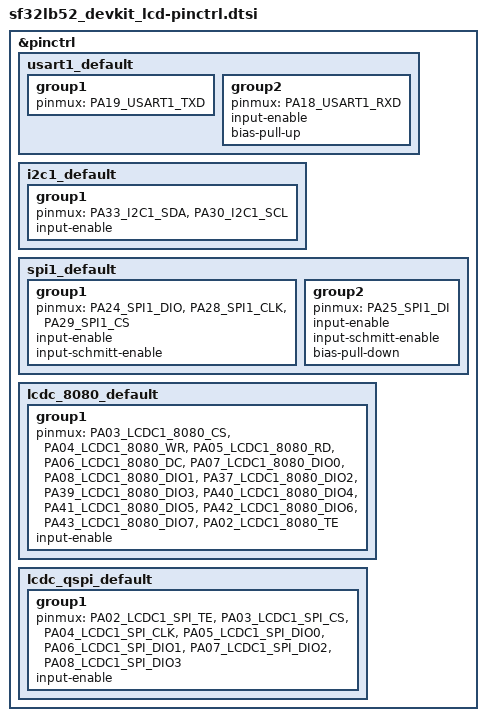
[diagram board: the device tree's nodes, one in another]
/*
 * Copyright (c) 2025 Core Devices LLC
 * SPDX-License-Identifier: Apache-2.0
 */

#include <zephyr/dt-bindings/pinctrl/sf32lb52x-pinctrl.h>

&pinctrl {
	usart1_default: usart1_default {
		group1 {
			pinmux = <PA19_USART1_TXD>;
		};

		group2 {
			pinmux = <PA18_USART1_RXD>;
			input-enable;
			bias-pull-up;
		};
	};

	i2c1_default: i2c1_default {
		group1 {
			pinmux = <PA33_I2C1_SDA>, <PA30_I2C1_SCL>;
			input-enable;
		};
	};

	spi1_default: spi1_default {
		group1 {
			pinmux = <PA24_SPI1_DIO>, <PA28_SPI1_CLK>, <PA29_SPI1_CS>;
			input-enable;
			input-schmitt-enable;
		};

		group2 {
			pinmux = <PA25_SPI1_DI>;
			input-enable;
			input-schmitt-enable;
			bias-pull-down;
		};
	};

	lcdc_8080_default: lcdc_8080_default {
		group1 {
			pinmux = <PA03_LCDC1_8080_CS>,
				 <PA04_LCDC1_8080_WR>,
				 <PA05_LCDC1_8080_RD>,
				 <PA06_LCDC1_8080_DC>,
				 <PA07_LCDC1_8080_DIO0>,
				 <PA08_LCDC1_8080_DIO1>,
				 <PA37_LCDC1_8080_DIO2>,
				 <PA39_LCDC1_8080_DIO3>,
				 <PA40_LCDC1_8080_DIO4>,
				 <PA41_LCDC1_8080_DIO5>,
				 <PA42_LCDC1_8080_DIO6>,
				 <PA43_LCDC1_8080_DIO7>,
				 <PA02_LCDC1_8080_TE>;
			input-enable;
		};
	};

	lcdc_qspi_default: lcdc_qspi_default {
		group1 {
			pinmux = <PA02_LCDC1_SPI_TE>,
				 <PA03_LCDC1_SPI_CS>,
				 <PA04_LCDC1_SPI_CLK>,
				 <PA05_LCDC1_SPI_DIO0>,
				 <PA06_LCDC1_SPI_DIO1>,
				 <PA07_LCDC1_SPI_DIO2>,
				 <PA08_LCDC1_SPI_DIO3>;
			input-enable;
		};
	};
};
